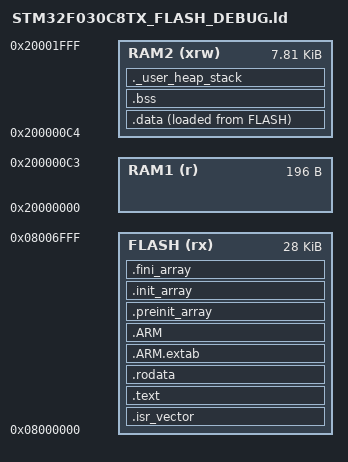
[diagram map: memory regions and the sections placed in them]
/*
******************************************************************************
**
** @file        : LinkerScript.ld
**
** @author      : Auto-generated by STM32CubeIDE
**
** @brief       : Linker script for STM32F030C8Tx Device from STM32F0 series
**                      64Kbytes FLASH
**                      8Kbytes RAM
**
**                Set heap size, stack size and stack location according
**                to application requirements.
**
**                Set memory bank area and size if external memory is used
**
**  Target      : STMicroelectronics STM32
**
**  Distribution: The file is distributed as is, without any warranty
**                of any kind.
**
******************************************************************************
** @attention
**
** Copyright (c) 2022 STMicroelectronics.
** All rights reserved.
**
** This software is licensed under terms that can be found in the LICENSE file
** in the root directory of this software component.
** If no LICENSE file comes with this software, it is provided AS-IS.
**
******************************************************************************
*/

/* Entry Point */
ENTRY(Reset_Handler)

/* Highest address of the user mode stack */
_estack = ORIGIN(RAM2) + LENGTH(RAM2); /* end of "RAM2" Ram type memory */

/* Application address */
_app_address = ORIGIN(FLASH) + LENGTH(FLASH);

/* Application flash pages */
_app_pages = 64 - (LENGTH(FLASH) / 1024);

/* Firmware updater enabler, placed by the application right after its
 * vector table in RAM1, see its .firmware_update_enabler section
 */
firmware_update_enabler = 0x200000c0;

_Min_Heap_Size = 0x200 ; /* required amount of heap */
_Min_Stack_Size = 0xc00; /* required amount of stack */

/* Memories definition
 * RAM1: Reserved, read only here so nothing is placed in it. The application
 *       keeps its vector table (Cortex-M0 has no VTOR) and
 *       firmware_update_enabler here, the enabler must survive the reset.
 * RAM2: Bootloader data, heap and stack, shared with the application. Only
 *       one of them runs at a time: main() resets all peripherals and
 *       interrupts before jumping to the application.
 */
MEMORY
{
  RAM1    (r)    : ORIGIN = 0x20000000,   LENGTH = 196
  RAM2    (xrw)    : ORIGIN = 0x200000C4,   LENGTH = 7996
  FLASH    (rx)    : ORIGIN = 0x8000000,   LENGTH = 28K
}

/* Sections */
SECTIONS
{
  /* The startup code into "FLASH" Rom type memory */
  .isr_vector :
  {
    . = ALIGN(4);
    KEEP(*(.isr_vector)) /* Startup code */
    . = ALIGN(4);
  } >FLASH

  /* The program code and other data into "FLASH" Rom type memory */
  .text :
  {
    . = ALIGN(4);
    *(.text)           /* .text sections (code) */
    *(.text*)          /* .text* sections (code) */
    *(.glue_7)         /* glue arm to thumb code */
    *(.glue_7t)        /* glue thumb to arm code */
    *(.eh_frame)

    KEEP (*(.init))
    KEEP (*(.fini))

    . = ALIGN(4);
    _etext = .;        /* define a global symbols at end of code */
  } >FLASH

  /* Constant data into "FLASH" Rom type memory */
  .rodata :
  {
    . = ALIGN(4);
    *(.rodata)         /* .rodata sections (constants, strings, etc.) */
    *(.rodata*)        /* .rodata* sections (constants, strings, etc.) */
    . = ALIGN(4);
  } >FLASH

  .ARM.extab   : {
    . = ALIGN(4);
    *(.ARM.extab* .gnu.linkonce.armextab.*)
    . = ALIGN(4);
  } >FLASH

  .ARM : {
    . = ALIGN(4);
    __exidx_start = .;
    *(.ARM.exidx*)
    __exidx_end = .;
    . = ALIGN(4);
  } >FLASH

  .preinit_array     :
  {
    . = ALIGN(4);
    PROVIDE_HIDDEN (__preinit_array_start = .);
    KEEP (*(.preinit_array*))
    PROVIDE_HIDDEN (__preinit_array_end = .);
    . = ALIGN(4);
  } >FLASH

  .init_array :
  {
    . = ALIGN(4);
    PROVIDE_HIDDEN (__init_array_start = .);
    KEEP (*(SORT(.init_array.*)))
    KEEP (*(.init_array*))
    PROVIDE_HIDDEN (__init_array_end = .);
    . = ALIGN(4);
  } >FLASH

  .fini_array :
  {
    . = ALIGN(4);
    PROVIDE_HIDDEN (__fini_array_start = .);
    KEEP (*(SORT(.fini_array.*)))
    KEEP (*(.fini_array*))
    PROVIDE_HIDDEN (__fini_array_end = .);
    . = ALIGN(4);
  } >FLASH

  /* Used by the startup to initialize data */
  _sidata = LOADADDR(.data);

  /* Initialized data sections into "RAM2" Ram type memory */
  .data :
  {
    . = ALIGN(4);
    _sdata = .;        /* create a global symbol at data start */
    *(.data)           /* .data sections */
    *(.data*)          /* .data* sections */
    *(.RamFunc)        /* .RamFunc sections */
    *(.RamFunc*)       /* .RamFunc* sections */

    . = ALIGN(4);
    _edata = .;        /* define a global symbol at data end */

  } >RAM2 AT> FLASH

  /* Uninitialized data section into "RAM2" Ram type memory */
  . = ALIGN(4);
  .bss :
  {
    /* This is used by the startup in order to initialize the .bss section */
    _sbss = .;         /* define a global symbol at bss start */
    __bss_start__ = _sbss;
    *(.bss)
    *(.bss*)
    *(COMMON)

    . = ALIGN(4);
    _ebss = .;         /* define a global symbol at bss end */
    __bss_end__ = _ebss;
  } >RAM2

  /* User_heap_stack section, used to check that there is enough "RAM2" Ram  type memory left */
  ._user_heap_stack :
  {
    . = ALIGN(8);
    PROVIDE ( end = . );
    PROVIDE ( _end = . );
    . = . + _Min_Heap_Size;
    . = . + _Min_Stack_Size;
    . = ALIGN(8);
  } >RAM2

  /* Remove information from the compiler libraries */
  /DISCARD/ :
  {
    libc.a ( * )
    libm.a ( * )
    libgcc.a ( * )
  }

  .ARM.attributes 0 : { *(.ARM.attributes) }

  /* Must match the application's FLASH origin (application Release + Boot Debug) */
  ASSERT(_app_address == 0x8007000,
         "Application start changed: update ORIGIN(FLASH) in mueb4-firmware-app/STM32F030C8TX_FLASH_BOOT_DEBUG.ld and this ASSERT")
}
